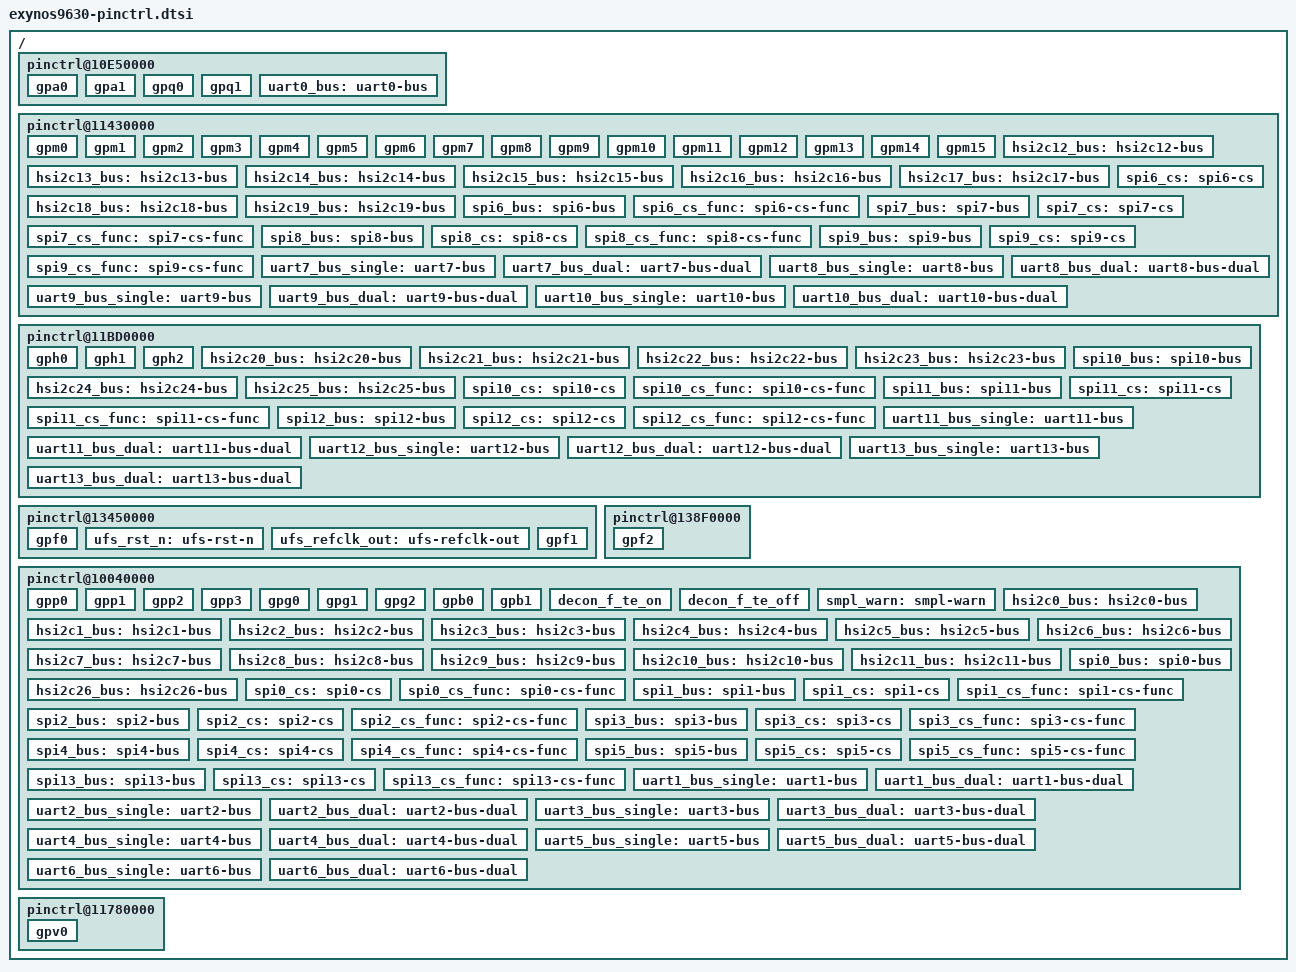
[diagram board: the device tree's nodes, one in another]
/*
 * Samsung's Exynos9630 SoC pin-mux and pin-config device tree source
 *
 * Copyright (c) 2019 Samsung Electronics Co., Ltd.
 *		http://www.samsung.com
 *
 * Samsung's Exynos9630 SoC pin-mux and pin-config options are listed as device
 * tree nodes are listed in this file.
 *
 * This program is free software; you can redistribute it and/or modify
 * it under the terms of the GNU General Public License version 2 as
 * published by the Free Software Foundation.
 */

/ {
	/* ALIVE */
	pinctrl@10E50000 {
		gpa0: gpa0 {
			gpio-controller;
			#gpio-cells = <2>;

			interrupt-controller;
			#interrupt-cells = <3>;
			interrupt-parent = <&gic>;
			interrupts = <GIC_SPI INTREQ__ALIVE_EINT0 IRQ_TYPE_LEVEL_HIGH>,
				     <GIC_SPI INTREQ__ALIVE_EINT1 IRQ_TYPE_LEVEL_HIGH>,
				     <GIC_SPI INTREQ__ALIVE_EINT2 IRQ_TYPE_LEVEL_HIGH>,
				     <GIC_SPI INTREQ__ALIVE_EINT3 IRQ_TYPE_LEVEL_HIGH>,
				     <GIC_SPI INTREQ__ALIVE_EINT4 IRQ_TYPE_LEVEL_HIGH>,
				     <GIC_SPI INTREQ__ALIVE_EINT5 IRQ_TYPE_LEVEL_HIGH>,
				     <GIC_SPI INTREQ__ALIVE_EINT6 IRQ_TYPE_LEVEL_HIGH>,
				     <GIC_SPI INTREQ__ALIVE_EINT7 IRQ_TYPE_LEVEL_HIGH>;
		};

		gpa1: gpa1 {
			gpio-controller;
			#gpio-cells = <2>;

			interrupt-controller;
			#interrupt-cells = <3>;
			interrupt-parent = <&gic>;
			interrupts = <GIC_SPI INTREQ__ALIVE_EINT8 IRQ_TYPE_LEVEL_HIGH>,
				     <GIC_SPI INTREQ__ALIVE_EINT9 IRQ_TYPE_LEVEL_HIGH>,
				     <GIC_SPI INTREQ__ALIVE_EINT10 IRQ_TYPE_LEVEL_HIGH>,
				     <GIC_SPI INTREQ__ALIVE_EINT11 IRQ_TYPE_LEVEL_HIGH>;
		};

		gpq0: gpq0 {
			gpio-controller;
			#gpio-cells = <2>;

			interrupt-controller;
			#interrupt-cells = <2>;
		};

		gpq1: gpq1 {
			gpio-controller;
			#gpio-cells = <2>;

			interrupt-controller;
			#interrupt-cells = <2>;
		};

		/* USI_PERI_UART_DBG */
		uart0_bus: uart0-bus {
			samsung,pins = "gpq0-0", "gpq0-1";
			samsung,pin-function = <2>;
			samsung,pin-pud = <0>;
		};
	};

	/* CMGP */
	pinctrl@11430000 {
		gpm0: gpm0 {
			gpio-controller;
			#gpio-cells = <2>;

			interrupt-controller;
			#interrupt-cells = <3>;
			interrupt-parent = <&gic>;
			interrupts = <GIC_SPI INTREQ__EXT_INTM00 IRQ_TYPE_LEVEL_HIGH>;
		};

		gpm1: gpm1 {
			gpio-controller;
			#gpio-cells = <2>;

			interrupt-controller;
			#interrupt-cells = <3>;
			interrupt-parent = <&gic>;
			interrupts = <GIC_SPI INTREQ__EXT_INTM01 IRQ_TYPE_LEVEL_HIGH>;
		};

		gpm2: gpm2 {
			gpio-controller;
			#gpio-cells = <2>;

			interrupt-controller;
			#interrupt-cells = <3>;
			interrupt-parent = <&gic>;
			interrupts = <GIC_SPI INTREQ__EXT_INTM02 IRQ_TYPE_LEVEL_HIGH>;
		};

		gpm3: gpm3 {
			gpio-controller;
			#gpio-cells = <2>;

			interrupt-controller;
			#interrupt-cells = <3>;
			interrupt-parent = <&gic>;
			interrupts = <GIC_SPI INTREQ__EXT_INTM03 IRQ_TYPE_LEVEL_HIGH>;
		};

		gpm4: gpm4 {
			gpio-controller;
			#gpio-cells = <2>;

			interrupt-controller;
			#interrupt-cells = <3>;
			interrupt-parent = <&gic>;
			interrupts = <GIC_SPI INTREQ__EXT_INTM04 IRQ_TYPE_LEVEL_HIGH>;
		};

		gpm5: gpm5 {
			gpio-controller;
			#gpio-cells = <2>;

			interrupt-controller;
			#interrupt-cells = <3>;
			interrupt-parent = <&gic>;
			interrupts = <GIC_SPI INTREQ__EXT_INTM05 IRQ_TYPE_LEVEL_HIGH>;
		};

		gpm6: gpm6 {
			gpio-controller;
			#gpio-cells = <2>;

			interrupt-controller;
			#interrupt-cells = <3>;
			interrupt-parent = <&gic>;
			interrupts = <GIC_SPI INTREQ__EXT_INTM06 IRQ_TYPE_LEVEL_HIGH>;
		};

		gpm7: gpm7 {
			gpio-controller;
			#gpio-cells = <2>;

			interrupt-controller;
			#interrupt-cells = <3>;
			interrupt-parent = <&gic>;
			interrupts = <GIC_SPI INTREQ__EXT_INTM07 IRQ_TYPE_LEVEL_HIGH>;
		};

		gpm8: gpm8 {
			gpio-controller;
			#gpio-cells = <2>;

			interrupt-controller;
			#interrupt-cells = <3>;
			interrupt-parent = <&gic>;
			interrupts = <GIC_SPI INTREQ__EXT_INTM08 IRQ_TYPE_LEVEL_HIGH>;
		};

		gpm9: gpm9 {
			gpio-controller;
			#gpio-cells = <2>;

			interrupt-controller;
			#interrupt-cells = <3>;
			interrupt-parent = <&gic>;
			interrupts = <GIC_SPI INTREQ__EXT_INTM09 IRQ_TYPE_LEVEL_HIGH>;
		};

		gpm10: gpm10 {
			gpio-controller;
			#gpio-cells = <2>;

			interrupt-controller;
			#interrupt-cells = <3>;
			interrupt-parent = <&gic>;
			interrupts = <GIC_SPI INTREQ__EXT_INTM10 IRQ_TYPE_LEVEL_HIGH>;
		};

		gpm11: gpm11 {
			gpio-controller;
			#gpio-cells = <2>;

			interrupt-controller;
			#interrupt-cells = <3>;
			interrupt-parent = <&gic>;
			interrupts = <GIC_SPI INTREQ__EXT_INTM11 IRQ_TYPE_LEVEL_HIGH>;
		};

		gpm12: gpm12 {
			gpio-controller;
			#gpio-cells = <2>;

			interrupt-controller;
			#interrupt-cells = <3>;
			interrupt-parent = <&gic>;
			interrupts = <GIC_SPI INTREQ__EXT_INTM12 IRQ_TYPE_LEVEL_HIGH>;
		};

		gpm13: gpm13 {
			gpio-controller;
			#gpio-cells = <2>;

			interrupt-controller;
			#interrupt-cells = <3>;
			interrupt-parent = <&gic>;
			interrupts = <GIC_SPI INTREQ__EXT_INTM13 IRQ_TYPE_LEVEL_HIGH>;
		};

		gpm14: gpm14 {
			gpio-controller;
			#gpio-cells = <2>;

			interrupt-controller;
			#interrupt-cells = <3>;
			interrupt-parent = <&gic>;
			interrupts = <GIC_SPI INTREQ__EXT_INTM14 IRQ_TYPE_LEVEL_HIGH>;
		};

		gpm15: gpm15 {
			gpio-controller;
			#gpio-cells = <2>;

			interrupt-controller;
			#interrupt-cells = <3>;
			interrupt-parent = <&gic>;
			interrupts = <GIC_SPI INTREQ__EXT_INTM15 IRQ_TYPE_LEVEL_HIGH>;
		};

		/* usi_cmgp00 */
		hsi2c12_bus: hsi2c12-bus {
			samsung,pins = "gpm0-0", "gpm1-0";
			samsung,pin-function = <2>;
			samsung,pin-pud = <3>;
			samsung,pin-drv = <0>;
		};

		/* usi_cmgp00_i2c */
		hsi2c13_bus: hsi2c13-bus {
			samsung,pins = "gpm2-0", "gpm3-0";
			samsung,pin-function = <3>;
			samsung,pin-pud = <3>;
			samsung,pin-drv = <0>;
		};

		/* usi_cmgp01 */
		hsi2c14_bus: hsi2c14-bus {
			samsung,pins = "gpm4-0", "gpm5-0";
			samsung,pin-function = <2>;
			samsung,pin-pud = <3>;
			samsung,pin-drv = <0>;
		};

		/* usi_cmgp01_i2c */
		hsi2c15_bus: hsi2c15-bus {
			samsung,pins = "gpm6-0", "gpm7-0";
			samsung,pin-function = <3>;
			samsung,pin-pud = <3>;
			samsung,pin-drv = <0>;
		};

		/* usi_cmgp02 */
		hsi2c16_bus: hsi2c16-bus {
			samsung,pins = "gpm8-0", "gpm9-0";
			samsung,pin-function = <2>;
			samsung,pin-pud = <3>;
			samsung,pin-drv = <0>;
		};

		/* usi_cmgp02_i2c */
		hsi2c17_bus: hsi2c17-bus {
			samsung,pins = "gpm10-0", "gpm11-0";
			samsung,pin-function = <3>;
			samsung,pin-pud = <3>;
			samsung,pin-drv = <0>;
		};

		/* usi_cmgp03 */
		hsi2c18_bus: hsi2c18-bus {
			samsung,pins = "gpm12-0", "gpm13-0";
			samsung,pin-function = <2>;
			samsung,pin-pud = <3>;
			samsung,pin-drv = <0>;
		};

		/* usi_cmgp03_i2c */
		hsi2c19_bus: hsi2c19-bus {
			samsung,pins = "gpm14-0", "gpm15-0";
			samsung,pin-function = <3>;
			samsung,pin-pud = <3>;
			samsung,pin-drv = <0>;
		};

		/* spi usi_cmgp00 */
		spi6_bus: spi6-bus {
			samsung,pins = "gpm0-0", "gpm1-0", "gpm2-0";
			samsung,pin-function = <2>;
			samsung,pin-pud = <0>;
			samsung,pin-drv = <0>;
		};

		spi6_cs: spi6-cs {
			samsung,pins = "gpm3-0";
			samsung,pin-function = <1>;
			samsung,pin-pud = <0>;
			samsung,pin-drv = <0>;
		};

		spi6_cs_func: spi6-cs-func {
			samsung,pins = "gpm3-0";
			samsung,pin-function = <2>;
			samsung,pin-pud = <0>;
			samsung,pin-drv = <0>;
		};

		/* spi usi_cmgp01 */
		spi7_bus: spi7-bus {
			samsung,pins = "gpm4-0", "gpm5-0", "gpm6-0";
			samsung,pin-function = <2>;
			samsung,pin-pud = <0>;
			samsung,pin-drv = <0>;
		};

		spi7_cs: spi7-cs {
			samsung,pins = "gpm7-0";
			samsung,pin-function = <1>;
			samsung,pin-pud = <0>;
			samsung,pin-drv = <0>;
		};

		spi7_cs_func: spi7-cs-func {
			samsung,pins = "gpm7-0";
			samsung,pin-function = <2>;
			samsung,pin-pud = <0>;
			samsung,pin-drv = <0>;
		};

		/* spi usi_cmgp02 */
		spi8_bus: spi8-bus {
			samsung,pins = "gpm8-0", "gpm9-0", "gpm10-0";
			samsung,pin-function = <2>;
			samsung,pin-pud = <0>;
			samsung,pin-drv = <0>;
		};

		spi8_cs: spi8-cs {
			samsung,pins = "gpm11-0";
			samsung,pin-function = <1>;
			samsung,pin-pud = <0>;
			samsung,pin-drv = <0>;
		};

		spi8_cs_func: spi8-cs-func {
			samsung,pins = "gpm11-0";
			samsung,pin-function = <2>;
			samsung,pin-pud = <0>;
			samsung,pin-drv = <0>;
		};

		/* spi usi_cmgp03 */
		spi9_bus: spi9-bus {
			samsung,pins = "gpm12-0", "gpm13-0", "gpm14-0";
			samsung,pin-function = <2>;
			samsung,pin-pud = <0>;
			samsung,pin-drv = <0>;
		};

		spi9_cs: spi9-cs {
			samsung,pins = "gpm15-0";
			samsung,pin-function = <1>;
			samsung,pin-pud = <0>;
			samsung,pin-drv = <0>;
		};

		spi9_cs_func: spi9-cs-func {
			samsung,pins = "gpm15-0";
			samsung,pin-function = <2>;
			samsung,pin-pud = <0>;
			samsung,pin-drv = <0>;
		};

		/* usi_cmgp00_uart */
		uart7_bus_single: uart7-bus {
			samsung,pins = "gpm0-0", "gpm1-0", "gpm2-0", "gpm3-0";
			samsung,pin-function = <2>;
			samsung,pin-pud = <0>;
		};

		uart7_bus_dual: uart7-bus-dual {
			samsung,pins = "gpm0-0", "gpm1-0";
			samsung,pin-function = <2>;
			samsung,pin-pud = <0>;
		};

		/* usi_cmgp01_uart */
		uart8_bus_single: uart8-bus {
			samsung,pins = "gpm4-0", "gpm5-0", "gpm6-0", "gpm7-0";
			samsung,pin-function = <2>;
			samsung,pin-pud = <0>;
		};

		uart8_bus_dual: uart8-bus-dual {
			samsung,pins = "gpm4-0", "gpm5-0";
			samsung,pin-function = <2>;
			samsung,pin-pud = <0>;
		};

		/* usi_cmgp02_uart */
		uart9_bus_single: uart9-bus {
			samsung,pins = "gpm8-0", "gpm9-0", "gpm10-0", "gpm11-0";
			samsung,pin-function = <2>;
			samsung,pin-pud = <0>;
		};

		uart9_bus_dual: uart9-bus-dual {
			samsung,pins = "gpm8-0", "gpm9-0";
			samsung,pin-function = <2>;
			samsung,pin-pud = <0>;
		};

		/* usi_cmgp03_uart */
		uart10_bus_single: uart10-bus {
			samsung,pins = "gpm12-0", "gpm13-0", "gpm14-0", "gpm15-0";
			samsung,pin-function = <2>;
			samsung,pin-pud = <0>;
		};

		uart10_bus_dual: uart10-bus-dual {
			samsung,pins = "gpm12-0", "gpm13-0";
			samsung,pin-function = <2>;
			samsung,pin-pud = <0>;
		};
	};

	/* CHUB */
	pinctrl@11BD0000 {
		gph0: gph0 {
			gpio-controller;
			#gpio-cells = <2>;

			interrupt-controller;
			#interrupt-cells = <2>;
			interrupt-parent = <&gic>;
			interrupts = <GIC_SPI INTREQ__EXT_INTH0_0 IRQ_TYPE_LEVEL_HIGH>,
				     <GIC_SPI INTREQ__EXT_INTH0_1 IRQ_TYPE_LEVEL_HIGH>,
				     <GIC_SPI INTREQ__EXT_INTH0_2 IRQ_TYPE_LEVEL_HIGH>,
				     <GIC_SPI INTREQ__EXT_INTH0_3 IRQ_TYPE_LEVEL_HIGH>,
				     <GIC_SPI INTREQ__EXT_INTH0_4 IRQ_TYPE_LEVEL_HIGH>,
				     <GIC_SPI INTREQ__EXT_INTH0_5 IRQ_TYPE_LEVEL_HIGH>,
				     <GIC_SPI INTREQ__EXT_INTH0_6 IRQ_TYPE_LEVEL_HIGH>,
				     <GIC_SPI INTREQ__EXT_INTH0_7 IRQ_TYPE_LEVEL_HIGH>;
		};

		gph1: gph1 {
			gpio-controller;
			#gpio-cells = <2>;

			interrupt-controller;
			#interrupt-cells = <2>;
			interrupt-parent = <&gic>;
			interrupts = <GIC_SPI INTREQ__EXT_INTH1_0 IRQ_TYPE_LEVEL_HIGH>,
				     <GIC_SPI INTREQ__EXT_INTH1_1 IRQ_TYPE_LEVEL_HIGH>,
				     <GIC_SPI INTREQ__EXT_INTH1_2 IRQ_TYPE_LEVEL_HIGH>,
				     <GIC_SPI INTREQ__EXT_INTH1_3 IRQ_TYPE_LEVEL_HIGH>;
		};

		gph2: gph2 {
			gpio-controller;
			#gpio-cells = <2>;

			interrupt-controller;
			#interrupt-cells = <2>;
			interrupt-parent = <&gic>;
			interrupts = <GIC_SPI INTREQ__EXT_INTH2_0 IRQ_TYPE_LEVEL_HIGH>,
				     <GIC_SPI INTREQ__EXT_INTH2_1 IRQ_TYPE_LEVEL_HIGH>,
				     <GIC_SPI INTREQ__EXT_INTH2_2 IRQ_TYPE_LEVEL_HIGH>,
				     <GIC_SPI INTREQ__EXT_INTH2_3 IRQ_TYPE_LEVEL_HIGH>,
				     <GIC_SPI INTREQ__EXT_INTH2_4 IRQ_TYPE_LEVEL_HIGH>,
				     <GIC_SPI INTREQ__EXT_INTH2_5 IRQ_TYPE_LEVEL_HIGH>;
		};

		/* usi_chub00 */
		hsi2c20_bus: hsi2c20-bus {
			samsung,pins = "gph0-0", "gph0-1";
			samsung,pin-function = <2>;
			samsung,pin-pud = <3>;
			samsung,pin-drv = <0>;
		};

		/* usi_chub00_i2c */
		hsi2c21_bus: hsi2c21-bus {
			samsung,pins = "gph0-2", "gph0-3";
			samsung,pin-function = <3>;
			samsung,pin-pud = <3>;
			samsung,pin-drv = <0>;
		};

		/* usi_chub01 */
		hsi2c22_bus: hsi2c22-bus {
			samsung,pins = "gph0-4", "gph0-5";
			samsung,pin-function = <2>;
			samsung,pin-pud = <3>;
			samsung,pin-drv = <0>;
		};

		/* usi_chub01_i2c */
		hsi2c23_bus: hsi2c23-bus {
			samsung,pins = "gph0-6", "gph0-7";
			samsung,pin-function = <3>;
			samsung,pin-pud = <3>;
			samsung,pin-drv = <0>;
		};

		/* usi_chub02 */
		hsi2c24_bus: hsi2c24-bus {
			samsung,pins = "gph1-0", "gph1-1";
			samsung,pin-function = <2>;
			samsung,pin-pud = <3>;
			samsung,pin-drv = <0>;
		};

		/* usi_chub02_i2c */
		hsi2c25_bus: hsi2c25-bus {
			samsung,pins = "gph1-2", "gph1-3";
			samsung,pin-function = <3>;
			samsung,pin-pud = <3>;
			samsung,pin-drv = <0>;
		};

		/* spi usi_chub00 */
		spi10_bus: spi10-bus {
			samsung,pins = "gph0-0", "gph0-1", "gph0-2";
			samsung,pin-function = <2>;
			samsung,pin-pud = <0>;
			samsung,pin-drv = <0>;
		};

		spi10_cs: spi10-cs {
			samsung,pins = "gph0-3";
			samsung,pin-function = <1>;
			samsung,pin-pud = <0>;
			samsung,pin-drv = <0>;
		};

		spi10_cs_func: spi10-cs-func {
			samsung,pins = "gph0-3";
			samsung,pin-function = <2>;
			samsung,pin-pud = <0>;
			samsung,pin-drv = <0>;
		};

		/* spi usi_chub01 */
		spi11_bus: spi11-bus {
			samsung,pins = "gph0-4", "gph0-5", "gph0-6";
			samsung,pin-function = <2>;
			samsung,pin-pud = <0>;
			samsung,pin-drv = <0>;
		};

		spi11_cs: spi11-cs {
			samsung,pins = "gph0-7";
			samsung,pin-function = <1>;
			samsung,pin-pud = <0>;
			samsung,pin-drv = <0>;
		};

		spi11_cs_func: spi11-cs-func {
			samsung,pins = "gph0-7";
			samsung,pin-function = <2>;
			samsung,pin-pud = <0>;
			samsung,pin-drv = <0>;
		};

		/* spi usi_chub02 */
		spi12_bus: spi12-bus {
			samsung,pins = "gph1-0", "gph1-1", "gph1-2";
			samsung,pin-function = <2>;
			samsung,pin-pud = <0>;
			samsung,pin-drv = <0>;
		};

		spi12_cs: spi12-cs {
			samsung,pins = "gph1-3";
			samsung,pin-function = <1>;
			samsung,pin-pud = <0>;
			samsung,pin-drv = <0>;
		};

		spi12_cs_func: spi12-cs-func {
			samsung,pins = "gph1-3";
			samsung,pin-function = <2>;
			samsung,pin-pud = <0>;
			samsung,pin-drv = <0>;
		};

		/* usi_chub00_uart */
		uart11_bus_single: uart11-bus {
			samsung,pins = "gph0-0", "gph0-1", "gph0-2", "gph0-3";
			samsung,pin-function = <2>;
			samsung,pin-pud = <0>;
		};

		uart11_bus_dual: uart11-bus-dual {
			samsung,pins = "gph0-0", "gph0-1";
			samsung,pin-function = <2>;
			samsung,pin-pud = <0>;
		};

		/* usi_chub01_uart */
		uart12_bus_single: uart12-bus {
			samsung,pins = "gph0-4", "gph0-5", "gph0-6", "gph0-7";
			samsung,pin-function = <2>;
			samsung,pin-pud = <0>;
		};

		uart12_bus_dual: uart12-bus-dual {
			samsung,pins = "gph0-4", "gph0-5";
			samsung,pin-function = <2>;
			samsung,pin-pud = <0>;
		};

		/* usi_chub02_uart */
		uart13_bus_single: uart13-bus {
			samsung,pins = "gph1-0", "gph1-1", "gph1-2", "gph1-3";
			samsung,pin-function = <2>;
			samsung,pin-pud = <0>;
		};

		uart13_bus_dual: uart13-bus-dual {
			samsung,pins = "gph1-0", "gph1-1";
			samsung,pin-function = <2>;
			samsung,pin-pud = <0>;
		};
	};

	/* HSI */
	pinctrl@13450000 {
		gpf0: gpf0 {
			gpio-controller;
			#gpio-cells = <2>;

			interrupt-controller;
			#interrupt-cells = <2>;
		};

		ufs_rst_n: ufs-rst-n {
			samsung,pins = "gpf0-1";
			samsung,pin-function = <3>;
			samsung,pin-pud = <0>;
			samsung,pin-con-pdn = <3>;
		};

		ufs_refclk_out: ufs-refclk-out {
			samsung,pins = "gpf0-0";
			samsung,pin-function = <3>;
			samsung,pin-pud = <0>;
			samsung,pin-con-pdn = <3>;
		};
		gpf1: gpf1 {
			gpio-controller;
			#gpio-cells = <2>;

			interrupt-controller;
			#interrupt-cells = <2>;
		};
	};

	/* MMCCARD */
	pinctrl@138F0000 {
		gpf2: gpf2 {
			gpio-controller;
			#gpio-cells = <2>;

			interrupt-controller;
			#interrupt-cells = <2>;
		};
	};

	/* PERI */
	pinctrl@10040000 {
		gpp0: gpp0 {
			gpio-controller;
			#gpio-cells = <2>;

			interrupt-controller;
			#interrupt-cells = <2>;
		};

		gpp1: gpp1 {
			gpio-controller;
			#gpio-cells = <2>;

			interrupt-controller;
			#interrupt-cells = <2>;
		};

		gpp2: gpp2 {
			gpio-controller;
			#gpio-cells = <2>;

			interrupt-controller;
			#interrupt-cells = <2>;
		};

		gpp3: gpp3 {
			gpio-controller;
			#gpio-cells = <2>;

			interrupt-controller;
			#interrupt-cells = <2>;
		};

		gpg0: gpg0 {
			gpio-controller;
			#gpio-cells = <2>;

			interrupt-controller;
			#interrupt-cells = <2>;
		};

		gpg1: gpg1 {
			gpio-controller;
			#gpio-cells = <2>;

			interrupt-controller;
			#interrupt-cells = <2>;
		};

		gpg2: gpg2 {
			gpio-controller;
			#gpio-cells = <2>;

			interrupt-controller;
			#interrupt-cells = <2>;
		};

		gpb0: gpb0 {
			gpio-controller;
			#gpio-cells = <2>;

			interrupt-controller;
			#interrupt-cells = <2>;
		};

		gpb1: gpb1 {
			gpio-controller;
			#gpio-cells = <2>;

			interrupt-controller;
			#interrupt-cells = <2>;
		      };

		decon_f_te_on: decon_f_te_on {
			samsung,pins = "gpg0-1";
			samsung,pin-function = <0xf>;
	       };

		decon_f_te_off: decon_f_te_off {
			samsung,pins = "gpg0-1";
			samsung,pin-function = <0>;
		};

		/* PMIC SMPL_WARN */
		smpl_warn: smpl-warn {
			samsung,pins = "gpg0-0";
			samsung,pin-function = <15>;
			samsung,pin-pud = <0>;
			samsung,pin-drv = <0>;
		};

		/* PERI USI00 */
		hsi2c0_bus: hsi2c0-bus {
			samsung,pins = "gpp0-0", "gpp0-1";
			samsung,pin-function = <2>;
			samsung,pin-pud = <3>;
			samsung,pin-drv = <0>;
		};

		/* PERI USI00_I2C */
		hsi2c1_bus: hsi2c1-bus {
			samsung,pins = "gpp0-2", "gpp0-3";
			samsung,pin-function = <3>;
			samsung,pin-pud = <3>;
			samsung,pin-drv = <0>;
		};

		/* PERI USI01 */
		hsi2c2_bus: hsi2c2-bus {
			samsung,pins = "gpp0-4", "gpp0-5";
			samsung,pin-function = <2>;
			samsung,pin-pud = <3>;
			samsung,pin-drv = <0>;
		};

		/* PERI USI01_I2C */
		hsi2c3_bus: hsi2c3-bus {
			samsung,pins = "gpp0-6", "gpp0-7";
			samsung,pin-function = <3>;
			samsung,pin-pud = <3>;
			samsung,pin-drv = <0>;
		};

		/* PERI USI02 */
		hsi2c4_bus: hsi2c4-bus {
			samsung,pins = "gpp1-0", "gpp1-1";
			samsung,pin-function = <2>;
			samsung,pin-pud = <3>;
			samsung,pin-drv = <0>;
		};

		/* PERI USI02_I2C */
		hsi2c5_bus: hsi2c5-bus {
			samsung,pins = "gpp1-2", "gpp1-3";
			samsung,pin-function = <3>;
			samsung,pin-pud = <3>;
			samsung,pin-drv = <0>;
		};

		/* PERI USI03 */
		hsi2c6_bus: hsi2c6-bus {
			samsung,pins = "gpp1-4", "gpp1-5";
			samsung,pin-function = <2>;
			samsung,pin-pud = <3>;
			samsung,pin-drv = <0>;
		};

		/* PERI USI03_I2C */
		hsi2c7_bus: hsi2c7-bus {
			samsung,pins = "gpp1-6", "gpp1-7";
			samsung,pin-function = <3>;
			samsung,pin-pud = <3>;
			samsung,pin-drv = <0>;
		};

		/* PERI USI04 */
		hsi2c8_bus: hsi2c8-bus {
			samsung,pins = "gpp2-0", "gpp2-1";
			samsung,pin-function = <2>;
			samsung,pin-pud = <3>;
			samsung,pin-drv = <0>;
		};

		/* PERI USI04_I2C */
		hsi2c9_bus: hsi2c9-bus {
			samsung,pins = "gpp2-2", "gpp2-3";
			samsung,pin-function = <3>;
			samsung,pin-pud = <3>;
			samsung,pin-drv = <0>;
		};

		/* PERI USI05 */
		hsi2c10_bus: hsi2c10-bus {
			samsung,pins = "gpp2-4", "gpp2-5";
			samsung,pin-function = <2>;
			samsung,pin-pud = <3>;
			samsung,pin-drv = <0>;
		};

		/* PERI USI05_I2C */
		hsi2c11_bus: hsi2c11-bus {
			samsung,pins = "gpp2-6", "gpp2-7";
			samsung,pin-function = <3>;
			samsung,pin-pud = <3>;
			samsung,pin-drv = <0>;
		};

		/* PERI I2C_OIS */
		hsi2c26_bus: hsi2c26-bus {
			samsung,pins = "gpp3-4", "gpp3-5";
			samsung,pin-function = <2>;
			samsung,pin-pud = <3>;
			samsung,pin-drv = <0>;
		};

		/* SPI USI_PERI_USI00_SPI */
		spi0_bus: spi0-bus {
			samsung,pins = "gpp0-2", "gpp0-1", "gpp0-0";
			samsung,pin-function = <2>;
			samsung,pin-pud = <0>;
			samsung,pin-drv = <0>;
		};

		spi0_cs: spi0-cs {
			samsung,pins = "gpp0-3";
			samsung,pin-function = <1>;
			samsung,pin-pud = <0>;
			samsung,pin-drv = <0>;
		};

		spi0_cs_func: spi0-cs-func {
			samsung,pins = "gpp0-3";
			samsung,pin-function = <2>;
			samsung,pin-pud = <0>;
			samsung,pin-drv = <0>;
		};

		/* PERI USI01_SPI */
		spi1_bus: spi1-bus {
			samsung,pins = "gpp0-6", "gpp0-5", "gpp0-4";
			samsung,pin-function = <2>;
			samsung,pin-pud = <0>;
			samsung,pin-drv = <0>;
		};

		spi1_cs: spi1-cs {
			samsung,pins = "gpp0-7";
			samsung,pin-function = <1>;
			samsung,pin-pud = <0>;
			samsung,pin-drv = <0>;
		};

		spi1_cs_func: spi1-cs-func {
			samsung,pins = "gpp0-7";
			samsung,pin-function = <2>;
			samsung,pin-pud = <0>;
			samsung,pin-drv = <0>;
		};

		/* PERI USI02_SPI */
		spi2_bus: spi2-bus {
			samsung,pins = "gpp1-2", "gpp1-1", "gpp1-0";
			samsung,pin-function = <2>;
			samsung,pin-pud = <0>;
			samsung,pin-drv = <0>;
		};

		spi2_cs: spi2-cs {
			samsung,pins = "gpp1-3";
			samsung,pin-function = <1>;
			samsung,pin-pud = <0>;
			samsung,pin-drv = <0>;
		};

		spi2_cs_func: spi2-cs-func {
			samsung,pins = "gpp1-3";
			samsung,pin-function = <2>;
			samsung,pin-pud = <0>;
			samsung,pin-drv = <0>;
		};

		/* PERI USI03_SPI */
		spi3_bus: spi3-bus {
			samsung,pins = "gpp1-6", "gpp1-5", "gpp1-4";
			samsung,pin-function = <2>;
			samsung,pin-pud = <0>;
			samsung,pin-drv = <0>;
		};

		spi3_cs: spi3-cs {
			samsung,pins = "gpp1-7";
			samsung,pin-function = <1>;
			samsung,pin-pud = <0>;
			samsung,pin-drv = <0>;
		};

		spi3_cs_func: spi3-cs-func {
			samsung,pins = "gpp1-7";
			samsung,pin-function = <2>;
			samsung,pin-pud = <0>;
			samsung,pin-drv = <0>;
		};

		/* PERI USI04_SPI */
		spi4_bus: spi4-bus {
			samsung,pins = "gpp2-2", "gpp2-1", "gpp2-0";
			samsung,pin-function = <2>;
			samsung,pin-pud = <0>;
			samsung,pin-drv = <0>;
		};

		spi4_cs: spi4-cs {
			samsung,pins = "gpp2-3";
			samsung,pin-function = <1>;
			samsung,pin-pud = <0>;
			samsung,pin-drv = <0>;
		};

		spi4_cs_func: spi4-cs-func {
			samsung,pins = "gpp2-3";
			samsung,pin-function = <2>;
			samsung,pin-pud = <0>;
			samsung,pin-drv = <0>;
		};

		/* PERI USI05_SPI */
		spi5_bus: spi5-bus {
			samsung,pins = "gpp2-6", "gpp2-5", "gpp2-4";
			samsung,pin-function = <2>;
			samsung,pin-pud = <0>;
			samsung,pin-drv = <0>;
		};

		spi5_cs: spi5-cs {
			samsung,pins = "gpp2-7";
			samsung,pin-function = <1>;
			samsung,pin-pud = <0>;
			samsung,pin-drv = <0>;
		};

		spi5_cs_func: spi5-cs-func {
			samsung,pins = "gpp2-7";
			samsung,pin-function = <2>;
			samsung,pin-pud = <0>;
			samsung,pin-drv = <0>;
		};

		/* PERI SPI_OIS */
		spi13_bus: spi13-bus {
			samsung,pins = "gpp3-2", "gpp3-1", "gpp3-0";
			samsung,pin-function = <2>;
			samsung,pin-pud = <0>;
			samsung,pin-drv = <0>;
		};

		spi13_cs: spi13-cs {
			samsung,pins = "gpp3-3";
			samsung,pin-function = <1>;
			samsung,pin-pud = <0>;
			samsung,pin-drv = <0>;
		};

		spi13_cs_func: spi13-cs-func {
			samsung,pins = "gpp3-3";
			samsung,pin-function = <2>;
			samsung,pin-pud = <0>;
			samsung,pin-drv = <0>;
		};

		/* USI_PERI_USI00_UART */
		uart1_bus_single: uart1-bus {
			samsung,pins = "gpp0-0", "gpp0-1", "gpp0-2", "gpp0-3";
			samsung,pin-function = <2>;
			samsung,pin-pud = <0>;
		};

		uart1_bus_dual: uart1-bus-dual {
			samsung,pins = "gpp0-0", "gpp0-1";
			samsung,pin-function = <2>;
			samsung,pin-pud = <0>;
		};

		/* USI_PERI_USI01_UART */
		uart2_bus_single: uart2-bus {
			samsung,pins = "gpp0-4", "gpp0-5", "gpp0-6", "gpp0-7";
			samsung,pin-function = <2>;
			samsung,pin-pud = <0>;
		};

		uart2_bus_dual: uart2-bus-dual {
			samsung,pins = "gpp0-4", "gpp0-5";
			samsung,pin-function = <2>;
			samsung,pin-pud = <0>;
		};

		/* USI_PERI_USI02_UART */
		uart3_bus_single: uart3-bus {
			samsung,pins = "gpp1-0", "gpp1-1", "gpp1-2", "gpp1-3";
			samsung,pin-function = <2>;
			samsung,pin-pud = <0>;
		};

		uart3_bus_dual: uart3-bus-dual {
			samsung,pins = "gpp1-0", "gpp1-1";
			samsung,pin-function = <2>;
			samsung,pin-pud = <0>;
		};

		/* USI_PERI_USI03_UART */
		uart4_bus_single: uart4-bus {
			samsung,pins = "gpp1-4", "gpp1-5", "gpp1-6", "gpp1-7";
			samsung,pin-function = <2>;
			samsung,pin-pud = <0>;
		};

		uart4_bus_dual: uart4-bus-dual {
			samsung,pins = "gpp1-4", "gpp1-5";
			samsung,pin-function = <2>;
			samsung,pin-pud = <0>;
		};

		/* USI_PERI_USI04_UART */
		uart5_bus_single: uart5-bus {
			samsung,pins = "gpp2-0", "gpp2-1", "gpp2-2", "gpp2-3";
			samsung,pin-function = <2>;
			samsung,pin-pud = <0>;
		};

		uart5_bus_dual: uart5-bus-dual {
			samsung,pins = "gpp2-0", "gpp2-1";
			samsung,pin-function = <2>;
			samsung,pin-pud = <0>;
		};

		/* USI_PERI_USI05_UART */
		uart6_bus_single: uart6-bus {
			samsung,pins = "gpp2-4", "gpp2-5", "gpp2-6", "gpp2-7";
			samsung,pin-function = <2>;
			samsung,pin-pud = <0>;
		};

		uart6_bus_dual: uart6-bus-dual {
			samsung,pins = "gpp2-4", "gpp2-5";
			samsung,pin-function = <2>;
			samsung,pin-pud = <0>;
		};
	};

	/* VTS */
	pinctrl@11780000 {
		gpv0: gpv0 {
			gpio-controller;
			#gpio-cells = <2>;

			interrupt-controller;
			#interrupt-cells = <2>;
		};
	};
};
